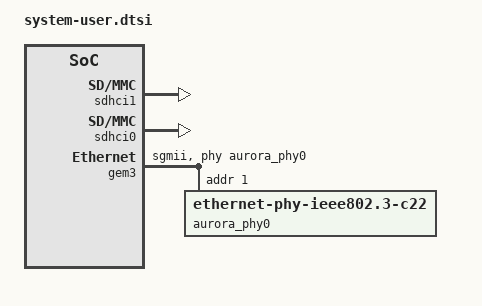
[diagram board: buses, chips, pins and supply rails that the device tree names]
/ {
    /* model = "Atlas-II Z8 HP"; */
    /* compatible = "iveia,atlas-ii-z8-hp", "xlnx,zynqmp-zcu102", "xlnx,zynqmp"; */

    aliases {
        ethernet0 = &gem3;
        gpio0 = &gpio;
        i2c0 = &i2c0;
        i2c1 = &i2c1;
        mmc0 = &sdhci0;
        mmc1 = &sdhci1;
        serial0 = &uart1;
        serial1 = &uart0;
        spi0 = &qspi;
        usb0 = &usb0;
    };

    pss_ref_clk: pss_ref_clk {
        clock-frequency = <50000000>;
    };
};

&qspi {
    is-dual = <0>;
};

&sdhci1 {
    status = "okay";
    no-1-8-v;       /* for 1.0 silicon */
    disable-wp;
};

&sdhci0 {
    status = "okay";
    no-1-8-v;       /* for 1.0 silicon */
    disable-wp;
};

&gem0 {
    status = "disabled";
};

&gem1 {
    status = "disabled";
};

&gem2 {
    status = "disabled";
};

// TODO: move to Aurora carrier DT Overlay
&gem3 {
    status = "okay";
    phy-handle = <&aurora_phy0>;
    phy-mode = "sgmii";
    use-internal-mdio = <1>;
    is-internal-pcspma = "true";
    
    aurora_phy0: phy@1 {
        reg = <1>;
        compatible = "ethernet-phy-ieee802.3-c22";
        device_type = "ethernet-phy";
    };

};

